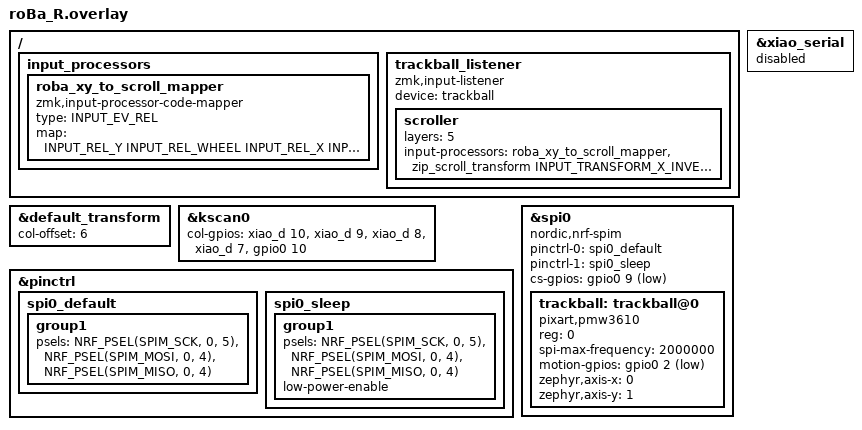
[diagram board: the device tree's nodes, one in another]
#include "roBa.dtsi"

#include <input/processors.dtsi>
#include <zephyr/dt-bindings/input/input-event-codes.h>
#include <dt-bindings/zmk/input_transform.h>

&default_transform {
    col-offset = <6>;
};

&kscan0 {
    col-gpios
        = <&xiao_d 10 GPIO_ACTIVE_HIGH>
        , <&xiao_d 9 GPIO_ACTIVE_HIGH>
        , <&xiao_d 8 GPIO_ACTIVE_HIGH>
        , <&xiao_d 7 GPIO_ACTIVE_HIGH>
        , <&gpio0 10 GPIO_ACTIVE_HIGH>
        ;
};

/ {
    input_processors {
        roba_xy_to_scroll_mapper: roba_xy_to_scroll_mapper {
            compatible = "zmk,input-processor-code-mapper";
            #input-processor-cells = <0>;
            type = <INPUT_EV_REL>;

            /*
             * roBa用のスクロール変換
             *
             * INPUT_REL_Y -> INPUT_REL_WHEEL
             * 上下の動きは、上下スクロールへ送る
             *
             * INPUT_REL_X -> INPUT_REL_HWHEEL
             * 左右の動きは、横スクロールへ送る
             */
            map = <
                INPUT_REL_Y INPUT_REL_WHEEL
                INPUT_REL_X INPUT_REL_HWHEEL
            >;
        };
    };

    trackball_listener {
        status = "okay";
        compatible = "zmk,input-listener";
        device = <&trackball>;

        scroller {
            layers = <5>;
            input-processors = <
                &roba_xy_to_scroll_mapper
                &zip_scroll_transform INPUT_TRANSFORM_X_INVERT
            >;
        };
    };
};

&pinctrl {
    spi0_default: spi0_default {
        group1 {
            psels = <NRF_PSEL(SPIM_SCK, 0, 5)>,
                <NRF_PSEL(SPIM_MOSI, 0, 4)>,
                <NRF_PSEL(SPIM_MISO, 0, 4)>;
        };
    };

    spi0_sleep: spi0_sleep {
        group1 {
            psels = <NRF_PSEL(SPIM_SCK, 0, 5)>,
                <NRF_PSEL(SPIM_MOSI, 0, 4)>,
                <NRF_PSEL(SPIM_MISO, 0, 4)>;
            low-power-enable;
        };
    };
};

&xiao_serial {
    status = "disabled";
};

&spi0 {
    status = "okay";
    compatible = "nordic,nrf-spim";
    pinctrl-0 = <&spi0_default>;
    pinctrl-1 = <&spi0_sleep>;
    pinctrl-names = "default", "sleep";
    cs-gpios = <&gpio0 9 GPIO_ACTIVE_LOW>;

    trackball: trackball@0 {
        status = "okay";
        compatible = "pixart,pmw3610";
        reg = <0>;
        spi-max-frequency = <2000000>;
        motion-gpios = <&gpio0 2 (GPIO_ACTIVE_LOW | GPIO_PULL_UP)>;
        zephyr,axis-x = <0>;
        zephyr,axis-y = <1>;
    };
};
